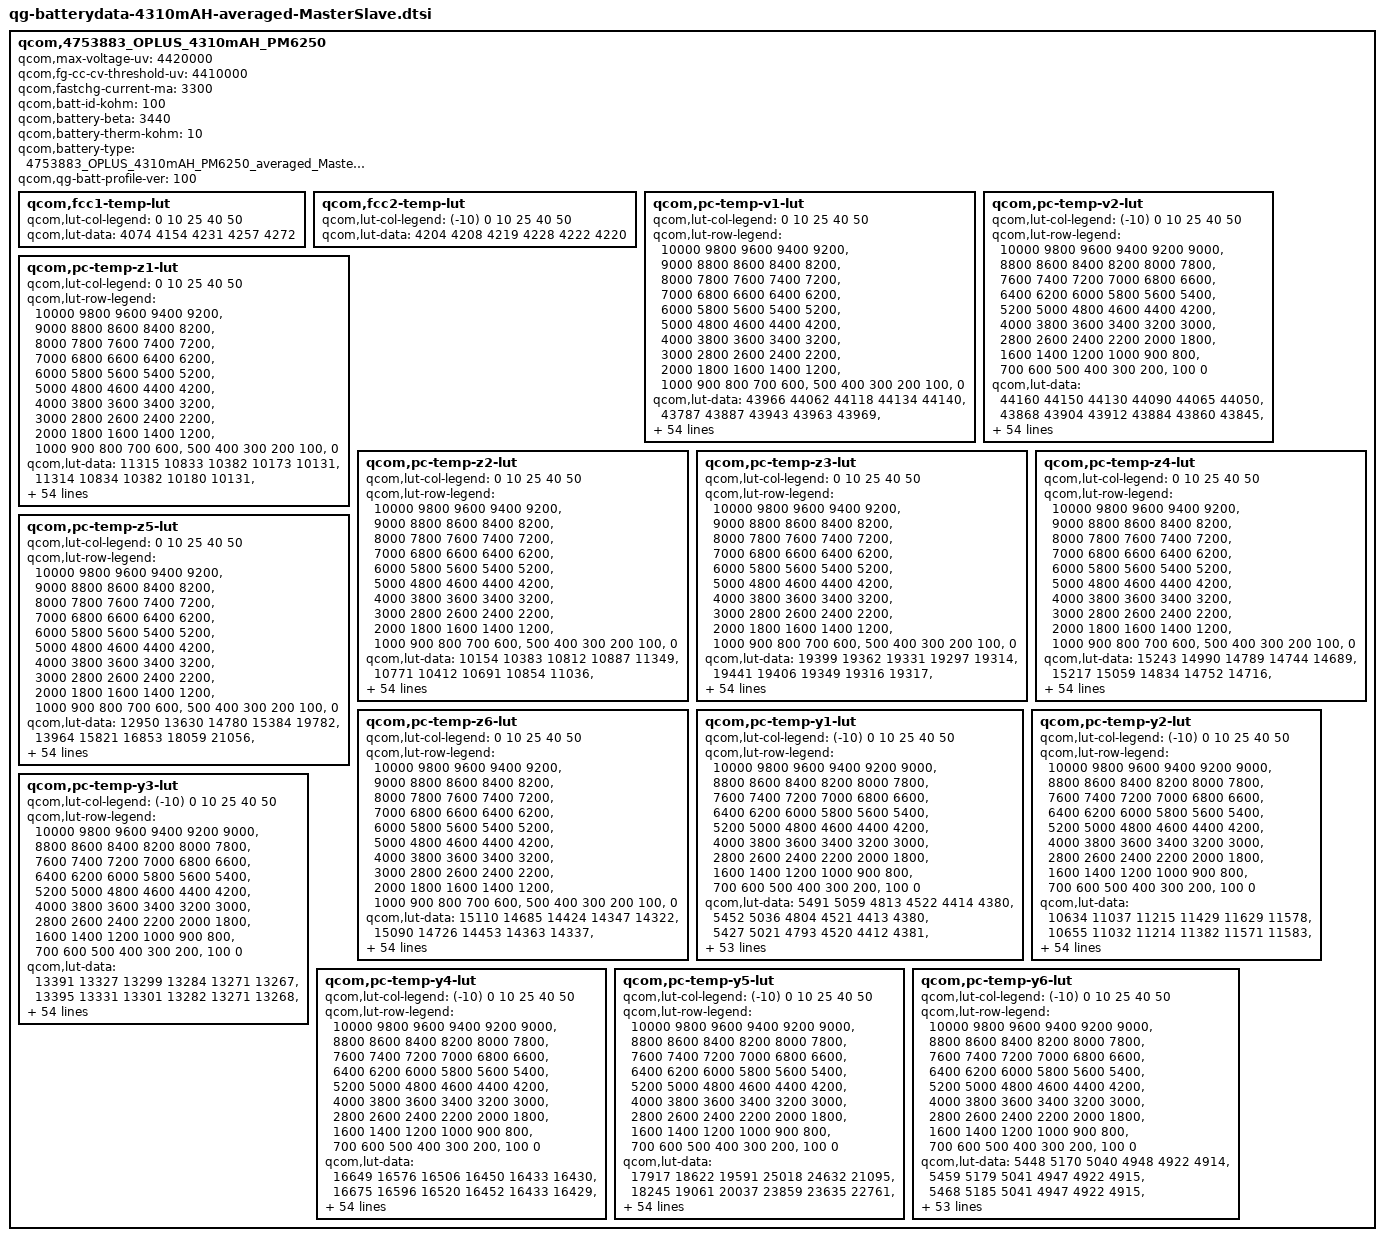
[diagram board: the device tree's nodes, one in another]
qcom,4753883_OPLUS_4310mAH_PM6250 {
    /* 4753883_OPLUS_4310mAH_PM6250_averaged_MasterSlave_Aug28th2020 */
    qcom,max-voltage-uv = <4420000>;
    qcom,fg-cc-cv-threshold-uv = <4410000>;
    qcom,fastchg-current-ma = <3300>;
    qcom,batt-id-kohm = <100>;
    qcom,battery-beta = <3440>;
    qcom,battery-therm-kohm = <10>;
    qcom,battery-type = "4753883_OPLUS_4310mAH_PM6250_averaged_MasterSlave_Aug28th2020";
    qcom,qg-batt-profile-ver = <100>;

	qcom,fcc1-temp-lut {
		qcom,lut-col-legend = <0 10 25 40 50>;
		qcom,lut-data = <4074 4154 4231 4257 4272>;
	};

	qcom,fcc2-temp-lut {
		qcom,lut-col-legend = <(-10) 0 10 25 40 50>;
		qcom,lut-data = <4204 4208 4219 4228 4222 4220>;
	};

	qcom,pc-temp-v1-lut {
		qcom,lut-col-legend = <0 10 25 40 50>;
		qcom,lut-row-legend = <10000 9800 9600 9400 9200>,
			<9000 8800 8600 8400 8200>,
			<8000 7800 7600 7400 7200>,
			<7000 6800 6600 6400 6200>,
			<6000 5800 5600 5400 5200>,
			<5000 4800 4600 4400 4200>,
			<4000 3800 3600 3400 3200>,
			<3000 2800 2600 2400 2200>,
			<2000 1800 1600 1400 1200>,
			<1000 900 800 700 600>,
			<500 400 300 200 100>,
			<0>;
		qcom,lut-data = <43966 44062 44118 44134 44140>,
			<43787 43887 43943 43963 43969>,
			<43591 43692 43756 43781 43788>,
			<43380 43486 43558 43588 43597>,
			<43146 43271 43349 43383 43395>,
			<42905 43043 43129 43170 43185>,
			<42672 42812 42898 42944 42962>,
			<42439 42578 42663 42712 42733>,
			<42211 42344 42426 42478 42501>,
			<41986 42111 42186 42239 42263>,
			<41765 41881 41953 42005 42029>,
			<41549 41655 41724 41772 41796>,
			<41335 41434 41499 41544 41568>,
			<41131 41220 41279 41321 41345>,
			<40941 41014 41063 41103 41127>,
			<40758 40818 40856 40894 40917>,
			<40572 40628 40656 40692 40712>,
			<40386 40443 40464 40496 40513>,
			<40189 40263 40286 40314 40328>,
			<39947 40064 40108 40138 40151>,
			<39655 39796 39893 39933 39952>,
			<39419 39511 39620 39668 39693>,
			<39276 39314 39375 39412 39434>,
			<39161 39176 39202 39228 39247>,
			<39054 39055 39059 39077 39095>,
			<38954 38936 38928 38943 38960>,
			<38860 38824 38809 38824 38835>,
			<38770 38723 38700 38716 38720>,
			<38683 38630 38600 38613 38613>,
			<38605 38543 38507 38515 38513>,
			<38535 38467 38423 38425 38421>,
			<38471 38396 38346 38341 38336>,
			<38414 38334 38276 38265 38258>,
			<38363 38278 38216 38195 38185>,
			<38317 38228 38162 38133 38117>,
			<38277 38182 38109 38068 38043>,
			<38240 38144 38059 37998 37958>,
			<38190 38097 38003 37922 37866>,
			<38100 38016 37925 37834 37769>,
			<37983 37902 37823 37733 37664>,
			<37859 37780 37707 37620 37548>,
			<37719 37644 37572 37486 37409>,
			<37561 37492 37425 37341 37260>,
			<37383 37315 37255 37176 37100>,
			<37242 37186 37129 37070 37001>,
			<37201 37111 37065 37011 36954>,
			<37177 37091 37044 36993 36937>,
			<37150 37074 37026 36982 36921>,
			<37111 37042 36996 36951 36884>,
			<36995 36921 36847 36782 36679>,
			<36641 36552 36468 36412 36305>,
			<36153 36065 35984 35938 35825>,
			<35531 35438 35357 35327 35205>,
			<34685 34579 34500 34495 34359>,
			<33337 33205 33147 33207 33041>,
			<30000 30000 30000 30000 30000>;
	};

	qcom,pc-temp-v2-lut {
		qcom,lut-col-legend = <(-10) 0 10 25 40 50>;
		qcom,lut-row-legend = <10000 9800 9600 9400 9200 9000>,
			<8800 8600 8400 8200 8000 7800>,
			<7600 7400 7200 7000 6800 6600>,
			<6400 6200 6000 5800 5600 5400>,
			<5200 5000 4800 4600 4400 4200>,
			<4000 3800 3600 3400 3200 3000>,
			<2800 2600 2400 2200 2000 1800>,
			<1600 1400 1200 1000 900 800>,
			<700 600 500 400 300 200>,
			<100 0>;
		qcom,lut-data = <44160 44150 44130 44090 44065 44050>,
			<43868 43904 43912 43884 43860 43845>,
			<43593 43666 43695 43675 43651 43637>,
			<43337 43437 43479 43463 43441 43428>,
			<43101 43218 43267 43247 43228 43216>,
			<42867 42998 43049 43026 43009 43000>,
			<42624 42765 42817 42796 42781 42772>,
			<42378 42525 42578 42559 42546 42538>,
			<42136 42286 42340 42323 42312 42305>,
			<41898 42045 42102 42085 42077 42071>,
			<41665 41807 41867 41850 41843 41838>,
			<41434 41576 41636 41619 41614 41609>,
			<41207 41351 41409 41392 41389 41384>,
			<41011 41135 41187 41171 41169 41164>,
			<40863 40927 40972 40953 40952 40948>,
			<40708 40726 40762 40743 40743 40740>,
			<40460 40534 40560 40544 40543 40540>,
			<40106 40350 40364 40352 40352 40349>,
			<39789 40140 40153 40158 40160 40158>,
			<39546 39866 39910 39961 39972 39971>,
			<39330 39574 39660 39756 39776 39777>,
			<39125 39332 39427 39520 39545 39549>,
			<38934 39118 39203 39252 39278 39285>,
			<38755 38931 39011 39034 39059 39068>,
			<38578 38773 38854 38880 38907 38918>,
			<38417 38633 38719 38752 38781 38792>,
			<38303 38505 38594 38630 38661 38673>,
			<38220 38387 38480 38517 38550 38561>,
			<38151 38278 38375 38415 38448 38458>,
			<38092 38168 38276 38321 38354 38361>,
			<38040 38067 38185 38234 38267 38272>,
			<37990 37994 38100 38152 38186 38191>,
			<37940 37943 38020 38075 38114 38119>,
			<37889 37899 37947 38000 38037 38041>,
			<37837 37861 37881 37928 37946 37935>,
			<37784 37827 37821 37855 37846 37811>,
			<37723 37786 37758 37770 37743 37695>,
			<37653 37736 37697 37669 37636 37585>,
			<37572 37672 37627 37566 37530 37480>,
			<37479 37585 37540 37476 37434 37385>,
			<37372 37465 37434 37390 37340 37296>,
			<37251 37325 37312 37283 37230 37187>,
			<37101 37145 37156 37141 37086 37034>,
			<36958 36978 37016 37014 36965 36909>,
			<36852 36856 36909 36913 36878 36828>,
			<36771 36779 36852 36875 36844 36794>,
			<36737 36750 36826 36857 36832 36783>,
			<36699 36723 36797 36835 36817 36767>,
			<36644 36672 36739 36793 36771 36701>,
			<36504 36532 36577 36632 36584 36460>,
			<36177 36174 36184 36247 36178 36032>,
			<35662 35653 35634 35723 35661 35500>,
			<34973 34973 34929 35056 34997 34812>,
			<34025 34044 33945 34162 34103 33885>,
			<32577 32550 32420 32709 32736 32404>,
			<28681 28719 28528 28518 29356 28748>;
	};

	qcom,pc-temp-z1-lut {
		qcom,lut-col-legend = <0 10 25 40 50>;
		qcom,lut-row-legend = <10000 9800 9600 9400 9200>,
			<9000 8800 8600 8400 8200>,
			<8000 7800 7600 7400 7200>,
			<7000 6800 6600 6400 6200>,
			<6000 5800 5600 5400 5200>,
			<5000 4800 4600 4400 4200>,
			<4000 3800 3600 3400 3200>,
			<3000 2800 2600 2400 2200>,
			<2000 1800 1600 1400 1200>,
			<1000 900 800 700 600>,
			<500 400 300 200 100>,
			<0>;
		qcom,lut-data = <11315 10833 10382 10173 10131>,
			<11314 10834 10382 10180 10131>,
			<11310 10826 10379 10183 10131>,
			<11302 10818 10372 10181 10131>,
			<11289 10809 10365 10178 10130>,
			<11274 10794 10359 10175 10130>,
			<11255 10779 10354 10173 10129>,
			<11230 10764 10349 10171 10128>,
			<11214 10749 10346 10169 10127>,
			<11206 10741 10343 10167 10127>,
			<11200 10737 10341 10166 10126>,
			<11191 10735 10338 10165 10125>,
			<11177 10734 10337 10165 10125>,
			<11168 10735 10335 10165 10125>,
			<11166 10735 10334 10165 10125>,
			<11165 10735 10334 10166 10125>,
			<11168 10736 10334 10166 10125>,
			<11180 10733 10335 10166 10125>,
			<11192 10724 10335 10166 10126>,
			<11189 10720 10337 10166 10127>,
			<11172 10723 10339 10167 10128>,
			<11161 10729 10342 10168 10129>,
			<11161 10734 10345 10169 10130>,
			<11162 10740 10347 10171 10132>,
			<11164 10744 10350 10173 10133>,
			<11167 10745 10353 10175 10135>,
			<11170 10746 10356 10177 10136>,
			<11172 10747 10360 10179 10137>,
			<11174 10754 10365 10181 10139>,
			<11176 10762 10369 10183 10140>,
			<11177 10764 10374 10185 10141>,
			<11179 10766 10377 10188 10143>,
			<11181 10767 10382 10190 10145>,
			<11186 10768 10386 10193 10147>,
			<11192 10771 10391 10196 10149>,
			<11206 10774 10396 10200 10150>,
			<11227 10778 10401 10202 10152>,
			<11236 10782 10406 10205 10154>,
			<11230 10788 10411 10208 10156>,
			<11222 10795 10416 10210 10158>,
			<11222 10801 10420 10212 10160>,
			<11229 10807 10425 10214 10160>,
			<11240 10815 10429 10216 10161>,
			<11261 10825 10434 10216 10162>,
			<11274 10829 10441 10218 10163>,
			<11249 10829 10447 10219 10163>,
			<11254 10827 10450 10219 10163>,
			<11267 10828 10448 10220 10164>,
			<11275 10828 10455 10222 10165>,
			<11280 10850 10454 10225 10166>,
			<11285 10851 10464 10227 10167>,
			<11286 10860 10471 10230 10170>,
			<11290 10892 10473 10234 10173>,
			<11313 10877 10490 10239 10178>,
			<11313 10877 10490 10239 10178>,
			<11313 10877 10490 10239 10178>;
	};

	qcom,pc-temp-z2-lut {
		qcom,lut-col-legend = <0 10 25 40 50>;
		qcom,lut-row-legend = <10000 9800 9600 9400 9200>,
			<9000 8800 8600 8400 8200>,
			<8000 7800 7600 7400 7200>,
			<7000 6800 6600 6400 6200>,
			<6000 5800 5600 5400 5200>,
			<5000 4800 4600 4400 4200>,
			<4000 3800 3600 3400 3200>,
			<3000 2800 2600 2400 2200>,
			<2000 1800 1600 1400 1200>,
			<1000 900 800 700 600>,
			<500 400 300 200 100>,
			<0>;
		qcom,lut-data = <10154 10383 10812 10887 11349>,
			<10771 10412 10691 10854 11036>,
			<11113 10466 10656 10814 10845>,
			<11124 10515 10655 10747 10803>,
			<10743 10514 10652 10666 10782>,
			<10385 10482 10645 10642 10770>,
			<10339 10457 10629 10652 10759>,
			<10319 10455 10614 10664 10753>,
			<10311 10459 10602 10667 10755>,
			<10309 10463 10590 10672 10763>,
			<10308 10470 10576 10678 10771>,
			<10312 10478 10559 10685 10789>,
			<10335 10484 10551 10692 10810>,
			<10357 10490 10555 10697 10820>,
			<10366 10495 10561 10701 10827>,
			<10373 10501 10562 10707 10834>,
			<10380 10505 10559 10720 10846>,
			<10387 10505 10558 10739 10858>,
			<10395 10502 10559 10754 10876>,
			<10407 10497 10562 10770 10915>,
			<10425 10474 10578 10797 10932>,
			<10435 10443 10643 10870 10904>,
			<10409 10447 10689 10930 10852>,
			<10367 10516 10674 10855 10778>,
			<10357 10572 10639 10659 10668>,
			<10374 10553 10610 10568 10620>,
			<10393 10507 10582 10543 10631>,
			<10402 10491 10566 10528 10650>,
			<10410 10499 10574 10542 10665>,
			<10414 10512 10598 10592 10683>,
			<10421 10524 10623 10630 10706>,
			<10431 10545 10655 10647 10749>,
			<10440 10563 10686 10664 10805>,
			<10448 10582 10706 10707 10863>,
			<10454 10600 10723 10790 10934>,
			<10453 10602 10736 10844 10984>,
			<10451 10593 10753 10864 11017>,
			<10451 10586 10771 10879 11045>,
			<10464 10603 10789 10905 11046>,
			<10480 10635 10818 10946 11031>,
			<10475 10642 10830 10965 11023>,
			<10441 10615 10827 10926 11045>,
			<10433 10600 10818 10888 11058>,
			<10446 10600 10782 10893 10996>,
			<10567 10645 10768 10898 10931>,
			<10449 10642 10758 10887 11001>,
			<12806 10624 10764 10921 11011>,
			<14762 10617 10754 10964 11045>,
			<13314 10626 10784 11028 11209>,
			<12415 10676 10785 10843 10832>,
			<11183 10733 10699 10697 10766>,
			<11710 10697 10646 10681 10712>,
			<15080 10662 10611 10636 10658>,
			<12762 10578 10581 10557 10557>,
			<12762 10578 10581 10557 10557>,
			<12762 10578 10581 10557 10557>;
	};

	qcom,pc-temp-z3-lut {
		qcom,lut-col-legend = <0 10 25 40 50>;
		qcom,lut-row-legend = <10000 9800 9600 9400 9200>,
			<9000 8800 8600 8400 8200>,
			<8000 7800 7600 7400 7200>,
			<7000 6800 6600 6400 6200>,
			<6000 5800 5600 5400 5200>,
			<5000 4800 4600 4400 4200>,
			<4000 3800 3600 3400 3200>,
			<3000 2800 2600 2400 2200>,
			<2000 1800 1600 1400 1200>,
			<1000 900 800 700 600>,
			<500 400 300 200 100>,
			<0>;
		qcom,lut-data = <19399 19362 19331 19297 19314>,
			<19441 19406 19349 19316 19317>,
			<19478 19433 19361 19329 19320>,
			<19506 19451 19372 19337 19324>,
			<19541 19460 19379 19343 19329>,
			<19567 19466 19379 19343 19330>,
			<19573 19469 19375 19339 19326>,
			<19576 19465 19373 19334 19322>,
			<19577 19459 19371 19333 19321>,
			<19574 19455 19370 19332 19321>,
			<19570 19453 19367 19332 19321>,
			<19565 19451 19361 19331 19320>,
			<19558 19449 19358 19330 19318>,
			<19551 19446 19357 19328 19316>,
			<19547 19444 19356 19326 19313>,
			<19544 19443 19355 19324 19311>,
			<19540 19441 19353 19321 19309>,
			<19534 19440 19352 19318 19308>,
			<19529 19439 19351 19317 19307>,
			<19536 19439 19351 19316 19305>,
			<19563 19439 19351 19317 19305>,
			<19579 19439 19354 19331 19319>,
			<19567 19441 19358 19346 19335>,
			<19548 19448 19370 19350 19336>,
			<19543 19456 19386 19353 19335>,
			<19547 19460 19390 19353 19334>,
			<19551 19464 19388 19349 19333>,
			<19551 19464 19385 19342 19331>,
			<19551 19461 19382 19338 19329>,
			<19551 19455 19377 19335 19325>,
			<19548 19451 19372 19332 19321>,
			<19544 19447 19368 19329 19317>,
			<19541 19444 19365 19326 19314>,
			<19539 19442 19362 19323 19309>,
			<19536 19441 19360 19319 19304>,
			<19535 19439 19359 19317 19301>,
			<19533 19438 19359 19319 19304>,
			<19531 19437 19358 19320 19308>,
			<19526 19433 19357 19323 19311>,
			<19520 19427 19355 19325 19314>,
			<19516 19424 19353 19327 19316>,
			<19513 19421 19353 19327 19316>,
			<19509 19418 19353 19327 19316>,
			<19500 19413 19352 19330 19318>,
			<19472 19396 19345 19323 19316>,
			<19311 19392 19333 19314 19302>,
			<19259 19389 19334 19313 19299>,
			<19258 19381 19332 19304 19296>,
			<19258 19379 19330 19300 19294>,
			<19258 19371 19337 19319 19308>,
			<19259 19355 19345 19321 19309>,
			<19259 19351 19345 19323 19309>,
			<19258 19352 19349 19324 19312>,
			<19259 19353 19350 19326 19316>,
			<19259 19353 19350 19326 19316>,
			<19259 19353 19350 19326 19316>;
	};

	qcom,pc-temp-z4-lut {
		qcom,lut-col-legend = <0 10 25 40 50>;
		qcom,lut-row-legend = <10000 9800 9600 9400 9200>,
			<9000 8800 8600 8400 8200>,
			<8000 7800 7600 7400 7200>,
			<7000 6800 6600 6400 6200>,
			<6000 5800 5600 5400 5200>,
			<5000 4800 4600 4400 4200>,
			<4000 3800 3600 3400 3200>,
			<3000 2800 2600 2400 2200>,
			<2000 1800 1600 1400 1200>,
			<1000 900 800 700 600>,
			<500 400 300 200 100>,
			<0>;
		qcom,lut-data = <15243 14990 14789 14744 14689>,
			<15217 15059 14834 14752 14716>,
			<15183 15022 14844 14754 14727>,
			<15139 14960 14814 14740 14719>,
			<15069 14908 14772 14713 14693>,
			<14998 14857 14745 14696 14678>,
			<14943 14815 14724 14687 14673>,
			<14894 14782 14710 14680 14669>,
			<14853 14756 14702 14674 14665>,
			<14817 14744 14696 14670 14661>,
			<14789 14739 14692 14666 14657>,
			<14777 14735 14690 14661 14654>,
			<14771 14731 14686 14656 14651>,
			<14767 14727 14682 14652 14647>,
			<14762 14725 14677 14648 14644>,
			<14758 14722 14674 14645 14641>,
			<14757 14720 14672 14643 14637>,
			<14767 14720 14671 14640 14634>,
			<14784 14721 14671 14638 14632>,
			<14812 14724 14670 14637 14630>,
			<14860 14773 14680 14639 14630>,
			<14886 14847 14738 14671 14655>,
			<14886 14861 14781 14702 14683>,
			<14884 14836 14766 14700 14683>,
			<14880 14808 14734 14687 14673>,
			<14857 14787 14716 14677 14664>,
			<14833 14770 14707 14673 14658>,
			<14822 14762 14701 14669 14654>,
			<14815 14759 14698 14665 14651>,
			<14813 14757 14696 14661 14649>,
			<14814 14758 14695 14658 14647>,
			<14815 14760 14695 14656 14644>,
			<14815 14762 14696 14654 14641>,
			<14815 14764 14697 14654 14640>,
			<14816 14766 14698 14653 14640>,
			<14813 14766 14700 14653 14640>,
			<14807 14762 14703 14660 14646>,
			<14801 14758 14705 14668 14655>,
			<14795 14754 14705 14669 14656>,
			<14788 14750 14703 14667 14653>,
			<14777 14743 14701 14665 14652>,
			<14758 14727 14691 14662 14654>,
			<14740 14712 14681 14660 14655>,
			<14721 14700 14674 14658 14655>,
			<14679 14672 14659 14646 14639>,
			<14819 14650 14646 14633 14627>,
			<14869 14645 14633 14625 14620>,
			<14864 14644 14625 14620 14613>,
			<14862 14643 14623 14618 14610>,
			<14862 14655 14627 14619 14622>,
			<14866 14678 14625 14623 14624>,
			<14868 14682 14624 14623 14626>,
			<14873 14682 14621 14623 14625>,
			<14877 14683 14622 14622 14623>,
			<14877 14683 14622 14622 14623>,
			<14877 14683 14622 14622 14623>;
	};

	qcom,pc-temp-z5-lut {
		qcom,lut-col-legend = <0 10 25 40 50>;
		qcom,lut-row-legend = <10000 9800 9600 9400 9200>,
			<9000 8800 8600 8400 8200>,
			<8000 7800 7600 7400 7200>,
			<7000 6800 6600 6400 6200>,
			<6000 5800 5600 5400 5200>,
			<5000 4800 4600 4400 4200>,
			<4000 3800 3600 3400 3200>,
			<3000 2800 2600 2400 2200>,
			<2000 1800 1600 1400 1200>,
			<1000 900 800 700 600>,
			<500 400 300 200 100>,
			<0>;
		qcom,lut-data = <12950 13630 14780 15384 19782>,
			<13964 15821 16853 18059 21056>,
			<14985 17278 18225 20124 22268>,
			<16040 18488 19131 21724 23824>,
			<17759 19659 19862 22924 25873>,
			<19681 20742 20489 23174 26546>,
			<21265 21787 21024 23099 26116>,
			<22762 22957 21542 23035 25710>,
			<24319 24131 22205 23377 25997>,
			<26201 24963 22721 24096 26996>,
			<27993 25521 22624 24768 27940>,
			<29224 26025 22036 25786 28893>,
			<30223 26591 21716 26770 29550>,
			<30796 27171 22157 27307 29486>,
			<30923 27799 22936 27686 29138>,
			<30856 28692 23526 27857 29016>,
			<30578 29417 24021 27835 30142>,
			<29505 29255 24520 27903 31695>,
			<28450 28288 25184 28474 32571>,
			<31178 27602 25788 29197 33257>,
			<41525 27466 25346 29252 33403>,
			<47843 27377 21958 26789 31017>,
			<41707 26957 19459 24271 27917>,
			<31559 25416 20230 24311 26648>,
			<28781 24256 22083 25163 25790>,
			<29698 25630 23821 25508 25511>,
			<31147 29071 25647 25354 26865>,
			<33079 31741 27387 25229 28876>,
			<35831 33775 28753 25621 30016>,
			<37836 35482 29962 27014 30845>,
			<39149 36662 31252 28357 31478>,
			<40109 37637 32771 29662 32009>,
			<40283 38172 34070 30724 32307>,
			<40240 38490 34979 31320 31914>,
			<40179 38728 35818 32140 30472>,
			<40032 38678 36070 32506 29533>,
			<39755 38103 35596 32084 29251>,
			<39548 37289 34718 31559 29080>,
			<39328 36124 33119 31696 30106>,
			<39024 34662 30395 32644 34641>,
			<38622 33735 29239 33804 37978>,
			<38069 33249 30307 35237 39352>,
			<37907 32675 31015 36571 40583>,
			<38420 31736 29918 38178 42246>,
			<41245 32540 28602 31907 39566>,
			<16425 35224 25934 27102 25206>,
			<11478 33829 30940 32067 26704>,
			<11409 28125 34530 29217 32885>,
			<11408 27134 33105 29114 36876>,
			<11435 22499 30941 42801 40783>,
			<11451 17251 33767 37360 36069>,
			<11402 16385 32359 36387 31836>,
			<11317 16133 34848 34005 31433>,
			<11258 16038 33619 32390 31383>,
			<11258 16038 33619 32390 31383>,
			<11258 16038 33619 32390 31383>;
	};

	qcom,pc-temp-z6-lut {
		qcom,lut-col-legend = <0 10 25 40 50>;
		qcom,lut-row-legend = <10000 9800 9600 9400 9200>,
			<9000 8800 8600 8400 8200>,
			<8000 7800 7600 7400 7200>,
			<7000 6800 6600 6400 6200>,
			<6000 5800 5600 5400 5200>,
			<5000 4800 4600 4400 4200>,
			<4000 3800 3600 3400 3200>,
			<3000 2800 2600 2400 2200>,
			<2000 1800 1600 1400 1200>,
			<1000 900 800 700 600>,
			<500 400 300 200 100>,
			<0>;
		qcom,lut-data = <15110 14685 14424 14347 14322>,
			<15090 14726 14453 14363 14337>,
			<15068 14712 14461 14370 14344>,
			<15042 14688 14451 14366 14342>,
			<15003 14664 14437 14358 14335>,
			<14961 14637 14424 14351 14329>,
			<14924 14611 14412 14344 14324>,
			<14885 14588 14403 14338 14320>,
			<14852 14569 14399 14335 14317>,
			<14821 14559 14395 14332 14315>,
			<14795 14553 14391 14330 14313>,
			<14782 14549 14386 14327 14311>,
			<14773 14545 14382 14324 14309>,
			<14766 14541 14379 14322 14306>,
			<14760 14538 14377 14319 14303>,
			<14755 14536 14375 14316 14301>,
			<14754 14533 14373 14313 14298>,
			<14755 14533 14372 14311 14296>,
			<14758 14532 14372 14310 14294>,
			<14770 14532 14372 14309 14293>,
			<14805 14554 14377 14310 14293>,
			<14826 14588 14405 14333 14312>,
			<14822 14595 14425 14354 14333>,
			<14815 14590 14424 14355 14334>,
			<14808 14583 14421 14352 14330>,
			<14802 14578 14417 14348 14326>,
			<14797 14574 14413 14344 14323>,
			<14795 14571 14409 14339 14320>,
			<14794 14568 14406 14336 14318>,
			<14794 14567 14403 14333 14315>,
			<14794 14567 14401 14330 14312>,
			<14795 14567 14400 14327 14309>,
			<14796 14568 14399 14325 14306>,
			<14797 14569 14399 14323 14303>,
			<14798 14571 14400 14322 14300>,
			<14799 14572 14400 14321 14299>,
			<14801 14572 14402 14325 14303>,
			<14802 14573 14404 14330 14309>,
			<14803 14572 14405 14331 14311>,
			<14803 14571 14404 14333 14312>,
			<14803 14569 14403 14333 14312>,
			<14801 14565 14400 14332 14313>,
			<14800 14562 14397 14331 14314>,
			<14799 14559 14394 14332 14316>,
			<14782 14545 14386 14324 14309>,
			<14765 14536 14375 14313 14295>,
			<14763 14533 14370 14309 14291>,
			<14764 14531 14367 14303 14285>,
			<14767 14531 14366 14299 14283>,
			<14774 14538 14372 14311 14297>,
			<14782 14544 14377 14315 14299>,
			<14791 14548 14379 14316 14301>,
			<14802 14554 14381 14318 14303>,
			<14817 14563 14384 14320 14305>,
			<14817 14563 14384 14320 14305>,
			<14817 14563 14384 14320 14305>;
	};

	qcom,pc-temp-y1-lut {
		qcom,lut-col-legend = <(-10) 0 10 25 40 50>;
		qcom,lut-row-legend = <10000 9800 9600 9400 9200 9000>,
			<8800 8600 8400 8200 8000 7800>,
			<7600 7400 7200 7000 6800 6600>,
			<6400 6200 6000 5800 5600 5400>,
			<5200 5000 4800 4600 4400 4200>,
			<4000 3800 3600 3400 3200 3000>,
			<2800 2600 2400 2200 2000 1800>,
			<1600 1400 1200 1000 900 800>,
			<700 600 500 400 300 200>,
			<100 0>;
		qcom,lut-data = <5491 5059 4813 4522 4414 4380>,
			<5452 5036 4804 4521 4413 4380>,
			<5427 5021 4793 4520 4412 4381>,
			<5411 5013 4782 4519 4411 4381>,
			<5405 5009 4773 4517 4410 4381>,
			<5405 5008 4767 4516 4409 4381>,
			<5417 5013 4763 4514 4408 4381>,
			<5437 5023 4761 4511 4408 4381>,
			<5443 5025 4759 4509 4407 4381>,
			<5433 5015 4758 4506 4406 4380>,
			<5424 5005 4756 4504 4405 4379>,
			<5417 5008 4753 4504 4404 4379>,
			<5403 5017 4748 4503 4403 4379>,
			<5399 5020 4744 4503 4403 4379>,
			<5414 5016 4740 4502 4402 4378>,
			<5430 5010 4737 4502 4402 4378>,
			<5430 5011 4737 4502 4402 4378>,
			<5424 5016 4739 4502 4404 4379>,
			<5419 5018 4741 4502 4404 4380>,
			<5415 5017 4743 4503 4403 4379>,
			<5411 5015 4747 4504 4403 4379>,
			<5417 5013 4748 4506 4403 4379>,
			<5441 5013 4748 4508 4404 4381>,
			<5457 5013 4748 4510 4405 4382>,
			<5452 5013 4749 4511 4407 4382>,
			<5442 5013 4750 4513 4408 4382>,
			<5434 5016 4750 4515 4409 4383>,
			<5420 5026 4750 4517 4410 4383>,
			<5411 5034 4751 4520 4411 4384>,
			<5409 5030 4753 4523 4412 4384>,
			<5409 5020 4756 4527 4413 4385>,
			<5409 5019 4759 4530 4414 4385>,
			<5412 5025 4762 4532 4416 4387>,
			<5416 5032 4765 4534 4418 4389>,
			<5415 5037 4768 4537 4419 4390>,
			<5410 5043 4771 4540 4420 4390>,
			<5409 5046 4774 4543 4421 4391>,
			<5415 5040 4779 4548 4423 4392>,
			<5421 5034 4782 4551 4424 4393>,
			<5419 5037 4784 4554 4425 4394>,
			<5413 5045 4786 4556 4426 4394>,
			<5410 5049 4789 4558 4426 4395>,
			<5415 5045 4796 4561 4428 4396>,
			<5422 5042 4802 4563 4429 4397>,
			<5430 5039 4808 4568 4430 4398>,
			<5434 5048 4814 4573 4432 4398>,
			<5435 5054 4816 4576 4434 4398>,
			<5458 5054 4819 4576 4434 4399>,
			<5515 5057 4824 4579 4433 4400>,
			<5474 5064 4823 4577 4433 4400>,
			<5527 5058 4833 4576 4434 4400>,
			<5550 5065 4840 4584 4435 4402>,
			<5600 5103 4851 4594 4438 4404>,
			<5634 5129 4852 4599 4441 4406>,
			<5634 5129 4852 4599 4441 4406>,
			<5634 5129 4852 4599 4441 4406>;
	};

	qcom,pc-temp-y2-lut {
		qcom,lut-col-legend = <(-10) 0 10 25 40 50>;
		qcom,lut-row-legend = <10000 9800 9600 9400 9200 9000>,
			<8800 8600 8400 8200 8000 7800>,
			<7600 7400 7200 7000 6800 6600>,
			<6400 6200 6000 5800 5600 5400>,
			<5200 5000 4800 4600 4400 4200>,
			<4000 3800 3600 3400 3200 3000>,
			<2800 2600 2400 2200 2000 1800>,
			<1600 1400 1200 1000 900 800>,
			<700 600 500 400 300 200>,
			<100 0>;
		qcom,lut-data = <10634 11037 11215 11429 11629 11578>,
			<10655 11032 11214 11382 11571 11583>,
			<10688 11023 11205 11336 11510 11583>,
			<10723 11013 11188 11293 11452 11581>,
			<10751 11002 11165 11254 11401 11575>,
			<10764 10991 11139 11219 11363 11567>,
			<10763 10974 11102 11188 11340 11538>,
			<10759 10950 11060 11160 11322 11487>,
			<10754 10933 11036 11137 11301 11448>,
			<10743 10916 11020 11113 11265 11382>,
			<10735 10906 11011 11097 11240 11329>,
			<10771 10910 11013 11103 11236 11325>,
			<10866 10925 11020 11122 11233 11329>,
			<10909 10949 11030 11135 11230 11320>,
			<10903 11014 11065 11143 11226 11292>,
			<10896 11084 11116 11153 11223 11269>,
			<10914 11117 11178 11184 11226 11274>,
			<10966 11138 11258 11258 11240 11303>,
			<10992 11154 11305 11346 11265 11340>,
			<10975 11169 11326 11486 11419 11411>,
			<10946 11180 11338 11603 11593 11493>,
			<10928 11173 11330 11570 11620 11553>,
			<10916 11136 11299 11421 11592 11623>,
			<10897 11113 11283 11347 11573 11668>,
			<10780 11122 11289 11384 11582 11684>,
			<10573 11136 11301 11436 11596 11696>,
			<10397 11139 11315 11452 11604 11719>,
			<10105 11138 11341 11456 11610 11765>,
			<9881 11137 11358 11464 11618 11808>,
			<9819 11136 11357 11509 11643 11847>,
			<9781 11134 11350 11565 11681 11884>,
			<9752 11130 11348 11579 11717 11889>,
			<9727 11115 11342 11573 11765 11877>,
			<9709 11095 11334 11566 11796 11868>,
			<9700 11077 11325 11555 11786 11874>,
			<9693 11053 11313 11539 11761 11890>,
			<9687 11022 11300 11531 11738 11893>,
			<9682 10976 11280 11525 11709 11874>,
			<9678 10915 11253 11522 11690 11851>,
			<9675 10842 11210 11516 11680 11835>,
			<9673 10748 11142 11499 11662 11822>,
			<9671 10598 11067 11487 11649 11808>,
			<9669 10145 10979 11442 11640 11788>,
			<9667 9802 10878 11408 11627 11751>,
			<9665 9734 10766 11365 11591 11628>,
			<9663 9700 10606 11310 11482 11498>,
			<9662 9690 10544 11277 11410 11453>,
			<9661 9684 10631 11283 11417 11440>,
			<9659 9678 10616 11339 11377 11424>,
			<9657 9672 10535 11329 11379 11417>,
			<9653 9667 10242 11257 11383 11344>,
			<9650 9662 10012 11166 11309 11320>,
			<9649 9656 9858 11107 11219 11227>,
			<9648 9651 9717 11083 11070 11033>,
			<9648 9651 9717 11083 11070 11033>,
			<9648 9651 9717 11083 11070 11033>;
	};

	qcom,pc-temp-y3-lut {
		qcom,lut-col-legend = <(-10) 0 10 25 40 50>;
		qcom,lut-row-legend = <10000 9800 9600 9400 9200 9000>,
			<8800 8600 8400 8200 8000 7800>,
			<7600 7400 7200 7000 6800 6600>,
			<6400 6200 6000 5800 5600 5400>,
			<5200 5000 4800 4600 4400 4200>,
			<4000 3800 3600 3400 3200 3000>,
			<2800 2600 2400 2200 2000 1800>,
			<1600 1400 1200 1000 900 800>,
			<700 600 500 400 300 200>,
			<100 0>;
		qcom,lut-data = <13391 13327 13299 13284 13271 13267>,
			<13395 13331 13301 13282 13271 13268>,
			<13400 13334 13303 13281 13271 13268>,
			<13404 13338 13305 13281 13272 13269>,
			<13408 13341 13307 13281 13272 13270>,
			<13411 13343 13308 13281 13273 13270>,
			<13415 13345 13309 13282 13273 13271>,
			<13418 13346 13309 13283 13274 13271>,
			<13418 13347 13310 13284 13274 13271>,
			<13418 13349 13311 13284 13274 13272>,
			<13416 13350 13312 13284 13275 13272>,
			<13411 13351 13313 13284 13275 13272>,
			<13401 13353 13314 13285 13276 13273>,
			<13395 13353 13314 13285 13276 13273>,
			<13393 13347 13314 13285 13276 13273>,
			<13391 13340 13314 13285 13276 13273>,
			<13388 13340 13313 13287 13277 13274>,
			<13383 13340 13310 13291 13279 13275>,
			<13377 13340 13307 13292 13280 13276>,
			<13371 13336 13306 13292 13281 13277>,
			<13366 13330 13305 13290 13281 13277>,
			<13362 13325 13303 13287 13280 13276>,
			<13358 13322 13300 13282 13274 13271>,
			<13354 13319 13298 13279 13271 13268>,
			<13346 13318 13297 13279 13271 13269>,
			<13335 13317 13296 13279 13271 13269>,
			<13331 13316 13296 13279 13271 13269>,
			<13331 13315 13296 13278 13271 13269>,
			<13334 13313 13296 13278 13270 13269>,
			<13339 13311 13296 13279 13271 13269>,
			<13348 13308 13295 13279 13271 13269>,
			<13357 13308 13295 13279 13272 13269>,
			<13365 13308 13294 13279 13271 13270>,
			<13373 13309 13294 13278 13271 13270>,
			<13386 13311 13293 13278 13271 13269>,
			<13402 13314 13292 13278 13271 13269>,
			<13422 13317 13292 13278 13271 13268>,
			<13445 13319 13292 13276 13270 13268>,
			<13472 13321 13293 13275 13270 13268>,
			<13504 13324 13294 13276 13270 13269>,
			<13542 13326 13295 13277 13271 13270>,
			<13587 13330 13297 13278 13271 13271>,
			<13636 13336 13298 13278 13271 13270>,
			<13697 13344 13300 13278 13271 13270>,
			<13783 13367 13304 13278 13271 13269>,
			<13908 13397 13310 13280 13273 13271>,
			<13982 13414 13311 13281 13275 13272>,
			<14046 13434 13313 13283 13276 13273>,
			<14182 13473 13319 13287 13276 13273>,
			<14382 13524 13324 13286 13275 13271>,
			<14902 13604 13327 13285 13274 13271>,
			<16344 13775 13339 13286 13275 13272>,
			<19511 14223 13369 13288 13277 13275>,
			<26755 15657 13457 13294 13279 13277>,
			<26755 15657 13457 13294 13279 13277>,
			<26755 15657 13457 13294 13279 13277>;
	};

	qcom,pc-temp-y4-lut {
		qcom,lut-col-legend = <(-10) 0 10 25 40 50>;
		qcom,lut-row-legend = <10000 9800 9600 9400 9200 9000>,
			<8800 8600 8400 8200 8000 7800>,
			<7600 7400 7200 7000 6800 6600>,
			<6400 6200 6000 5800 5600 5400>,
			<5200 5000 4800 4600 4400 4200>,
			<4000 3800 3600 3400 3200 3000>,
			<2800 2600 2400 2200 2000 1800>,
			<1600 1400 1200 1000 900 800>,
			<700 600 500 400 300 200>,
			<100 0>;
		qcom,lut-data = <16649 16576 16506 16450 16433 16430>,
			<16675 16596 16520 16452 16433 16429>,
			<16723 16622 16531 16453 16432 16429>,
			<16777 16647 16540 16454 16432 16428>,
			<16823 16668 16546 16455 16432 16428>,
			<16845 16677 16548 16455 16432 16428>,
			<16843 16675 16545 16455 16432 16427>,
			<16839 16671 16540 16454 16432 16427>,
			<16839 16667 16539 16454 16432 16427>,
			<16845 16663 16539 16456 16433 16428>,
			<16857 16660 16539 16459 16435 16429>,
			<16881 16663 16542 16462 16437 16430>,
			<16924 16673 16548 16466 16439 16432>,
			<16974 16689 16557 16470 16442 16433>,
			<17051 16737 16573 16477 16446 16436>,
			<17113 16793 16595 16485 16451 16440>,
			<17075 16823 16629 16495 16456 16444>,
			<16919 16844 16678 16506 16463 16448>,
			<16804 16851 16697 16521 16472 16456>,
			<16760 16787 16668 16548 16496 16476>,
			<16727 16689 16620 16571 16518 16495>,
			<16689 16634 16578 16555 16508 16488>,
			<16648 16595 16533 16494 16464 16453>,
			<16614 16570 16508 16460 16439 16433>,
			<16585 16556 16500 16456 16438 16432>,
			<16562 16546 16496 16454 16437 16431>,
			<16559 16536 16495 16454 16437 16432>,
			<16573 16527 16494 16456 16440 16433>,
			<16587 16517 16494 16460 16443 16435>,
			<16591 16501 16495 16464 16446 16438>,
			<16594 16483 16496 16470 16450 16441>,
			<16599 16479 16496 16475 16455 16445>,
			<16608 16485 16494 16481 16464 16453>,
			<16619 16494 16492 16483 16469 16458>,
			<16628 16507 16490 16483 16465 16453>,
			<16636 16524 16487 16481 16458 16443>,
			<16643 16541 16486 16477 16451 16438>,
			<16648 16560 16487 16456 16444 16436>,
			<16652 16574 16489 16441 16439 16435>,
			<16652 16573 16491 16441 16439 16438>,
			<16651 16565 16495 16443 16440 16446>,
			<16648 16562 16501 16446 16440 16448>,
			<16637 16563 16510 16450 16439 16445>,
			<16629 16564 16518 16452 16437 16439>,
			<16633 16567 16526 16451 16427 16423>,
			<16650 16584 16547 16463 16431 16428>,
			<16666 16599 16550 16466 16439 16443>,
			<16673 16606 16547 16472 16465 16489>,
			<16704 16632 16571 16502 16507 16517>,
			<16727 16655 16583 16500 16484 16465>,
			<16763 16647 16575 16471 16437 16436>,
			<17043 16665 16588 16476 16440 16440>,
			<18100 16753 16625 16497 16450 16449>,
			<23847 17515 16695 16540 16482 16489>,
			<23847 17515 16695 16540 16482 16489>,
			<23847 17515 16695 16540 16482 16489>;
	};

	qcom,pc-temp-y5-lut {
		qcom,lut-col-legend = <(-10) 0 10 25 40 50>;
		qcom,lut-row-legend = <10000 9800 9600 9400 9200 9000>,
			<8800 8600 8400 8200 8000 7800>,
			<7600 7400 7200 7000 6800 6600>,
			<6400 6200 6000 5800 5600 5400>,
			<5200 5000 4800 4600 4400 4200>,
			<4000 3800 3600 3400 3200 3000>,
			<2800 2600 2400 2200 2000 1800>,
			<1600 1400 1200 1000 900 800>,
			<700 600 500 400 300 200>,
			<100 0>;
		qcom,lut-data = <17917 18622 19591 25018 24632 21095>,
			<18245 19061 20037 23859 23635 22761>,
			<18701 19521 20306 22419 22788 24048>,
			<19185 19941 20441 20986 22108 24979>,
			<19599 20258 20481 19846 21619 25576>,
			<19842 20411 20467 19291 21340 25862>,
			<19932 20398 20263 19367 21367 25679>,
			<19993 20311 19805 19576 21545 25188>,
			<19970 20162 19375 19442 21401 24933>,
			<19518 19697 18967 18655 20548 23971>,
			<18801 19111 18522 17792 19666 22967>,
			<17734 18648 18004 17300 19236 22264>,
			<16282 18196 17414 16909 18866 21074>,
			<15857 17577 16788 16422 18355 20070>,
			<18072 16300 15910 15632 17281 19131>,
			<20673 15213 15254 15049 16414 18484>,
			<21266 16170 15326 15161 16425 18431>,
			<21456 19724 15835 15701 16675 18550>,
			<21720 22065 16658 16461 17009 18745>,
			<22313 22866 19378 18150 18011 19327>,
			<23045 23362 22381 19857 19217 20020>,
			<23655 23476 23215 20396 19748 20339>,
			<24262 23503 23558 20671 20060 20517>,
			<24554 23557 23736 20950 20350 20782>,
			<21962 23888 23892 21788 20736 21770>,
			<17318 24418 24077 22656 21051 22918>,
			<15188 24825 24307 22554 20872 22863>,
			<13918 25232 24715 21665 19897 21611>,
			<13255 25462 25056 21144 19251 20505>,
			<13376 24050 25248 21586 19411 19911>,
			<13651 21171 25415 22212 19688 19453>,
			<13778 19924 25617 22272 19587 19375>,
			<13803 19643 26173 21979 19059 19500>,
			<13831 19685 26593 21835 18700 19679>,
			<13992 20305 25790 22501 19713 20117>,
			<14347 21435 24024 23552 21630 20916>,
			<14605 22125 23032 23698 22197 21471>,
			<14756 22512 22589 22964 22047 22211>,
			<14863 22751 22235 22409 21943 23212>,
			<14922 22863 21811 22830 22506 25212>,
			<14965 23116 21313 23634 23852 28534>,
			<14969 23124 20799 23788 24833 30256>,
			<14303 18992 19781 23003 25495 30406>,
			<13671 15679 19343 22265 25583 29891>,
			<13532 15491 20251 21550 24378 27296>,
			<13513 14826 19484 19208 22358 27033>,
			<13518 14393 18644 18672 23929 25711>,
			<13621 14579 18744 20352 25296 21966>,
			<14038 14834 18441 21853 19908 17813>,
			<13932 14781 18910 21891 19422 19050>,
			<13116 14487 18669 24225 24416 23395>,
			<11270 14555 17695 24089 25248 24159>,
			<10004 13500 16992 23329 26298 27291>,
			<9177 10757 15588 24215 27188 27317>,
			<9177 10757 15588 24215 27188 27317>,
			<9177 10757 15588 24215 27188 27317>;
	};

	qcom,pc-temp-y6-lut {
		qcom,lut-col-legend = <(-10) 0 10 25 40 50>;
		qcom,lut-row-legend = <10000 9800 9600 9400 9200 9000>,
			<8800 8600 8400 8200 8000 7800>,
			<7600 7400 7200 7000 6800 6600>,
			<6400 6200 6000 5800 5600 5400>,
			<5200 5000 4800 4600 4400 4200>,
			<4000 3800 3600 3400 3200 3000>,
			<2800 2600 2400 2200 2000 1800>,
			<1600 1400 1200 1000 900 800>,
			<700 600 500 400 300 200>,
			<100 0>;
		qcom,lut-data = <5448 5170 5040 4948 4922 4914>,
			<5459 5179 5041 4947 4922 4915>,
			<5468 5185 5041 4947 4922 4915>,
			<5474 5188 5042 4947 4922 4916>,
			<5478 5189 5042 4947 4922 4916>,
			<5479 5190 5042 4947 4922 4916>,
			<5478 5188 5040 4947 4923 4917>,
			<5473 5184 5037 4947 4923 4917>,
			<5470 5181 5035 4948 4923 4917>,
			<5468 5177 5034 4948 4924 4918>,
			<5466 5175 5034 4949 4924 4918>,
			<5468 5176 5034 4950 4925 4919>,
			<5472 5177 5035 4951 4926 4919>,
			<5479 5180 5037 4953 4927 4920>,
			<5500 5188 5041 4955 4928 4921>,
			<5519 5198 5047 4957 4930 4922>,
			<5509 5206 5055 4961 4932 4924>,
			<5464 5214 5066 4966 4935 4926>,
			<5431 5216 5070 4972 4939 4929>,
			<5418 5195 5061 4979 4946 4935>,
			<5409 5164 5047 4984 4952 4941>,
			<5400 5146 5033 4979 4948 4938>,
			<5391 5133 5018 4957 4932 4924>,
			<5384 5126 5010 4945 4922 4916>,
			<5377 5124 5008 4944 4922 4916>,
			<5372 5122 5007 4944 4922 4916>,
			<5372 5122 5007 4944 4922 4916>,
			<5381 5121 5008 4945 4922 4916>,
			<5395 5121 5009 4946 4923 4917>,
			<5409 5120 5010 4948 4924 4918>,
			<5425 5117 5011 4950 4926 4919>,
			<5443 5117 5012 4952 4928 4921>,
			<5463 5124 5013 4954 4930 4923>,
			<5485 5135 5013 4955 4931 4925>,
			<5510 5147 5014 4955 4931 4923>,
			<5539 5162 5014 4955 4929 4920>,
			<5569 5179 5015 4954 4927 4918>,
			<5600 5197 5018 4948 4924 4918>,
			<5634 5216 5022 4943 4923 4918>,
			<5671 5236 5026 4943 4923 4919>,
			<5712 5256 5033 4945 4924 4922>,
			<5756 5278 5040 4947 4925 4923>,
			<5803 5300 5051 4949 4925 4922>,
			<5861 5329 5064 4951 4924 4920>,
			<5945 5371 5082 4952 4921 4916>,
			<6068 5432 5109 4958 4924 4918>,
			<6144 5467 5113 4959 4928 4924>,
			<6213 5499 5114 4963 4937 4937>,
			<6347 5556 5136 4975 4948 4945>,
			<6547 5627 5158 4973 4941 4929>,
			<7055 5718 5177 4965 4927 4921>,
			<8347 5901 5224 4968 4929 4923>,
			<11049 6361 5312 4977 4933 4928>,
			<17620 7788 5467 4996 4945 4942>,
			<17620 7788 5467 4996 4945 4942>,
			<17620 7788 5467 4996 4945 4942>;
	};

};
